# CC3200 register map
Vendor: Texas Instruments; File version: 1.0
SimpleLink™ 32-bit Arm Cortex-M4 Wi-Fi® wireless MCU with 2 TLS/SSL and 256kB RAM
CPU: CM4 r2p1, little endian, no MPU, no FPU, 3 interrupt priority bits
Registers are 32-bit, read-write, reset 0x0 unless marked. A register's access mark holds for its fields unless they carry their own. Offsets are from the block's base; lines under a group give offsets from that group; [hi:lo] are bit positions; {n}, {i} and the like mark numbered series; 'fields as' and 'values as' point back to an identical list; <NAME> marks a mode.

## Memory map
0x40000000 WDT size 0x1000 — Watchdog Timer
0x40004000 GPIOA0 size 0x1000 — General-Purpose Input/Output Port A0
0x40005000 GPIOA1 size 0x1000 — General-Purpose Input/Output Port A1
0x40006000 GPIOA2 size 0x1000 — General-Purpose Input/Output Port A2
0x40007000 GPIOA3 size 0x1000 — General-Purpose Input/Output Port A3
0x44025000 ARCM size 0x1000 — Application Reset-Clock Manager
0x4402E000 OCP_SHARED size 0x1000 — MCU Shared Configuration

## WDT — Watchdog Timer
Base 0x40000000
0x00 WDTLOAD reset 0xFFFFFFFF — Watchdog Load
  [31:0] WDTLOAD — Watchdog Load Value
0x04 WDTVALUE ro reset 0xFFFFFFFF — Watchdog Value
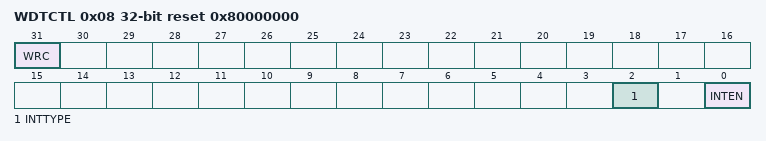
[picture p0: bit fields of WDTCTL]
0x08 WDTCTL reset 0x80000000 — Watchdog Control
  [31] WRC ro — Write Complete
  [2] INTTYPE — Watchdog Interrupt Type
  [0] INTEN — Watchdog Interrupt Enable
0x0C WDTICR wo reset not defined — Watchdog Interrupt Clear
  [31:0] WDTINTCLR
0x10 WDTRIS ro — Watchdog Raw Interrupt Status
  [0] WDTRIS
0x418 WDTTEST — Watchdog Test Mode
  [8] STALL — Watchdog Stall Enable
0xC00 WDTLOCK — Watchdog Lock

## GPIOA0 — General-Purpose Input/Output Port A0
Base 0x40004000
Same registers: GPIOA1 0x40005000, GPIOA2 0x40006000, GPIOA3 0x40007000
0x3FC GPIODATA
  [7:0] DATA
0x400 GPIODIR — GPIO Data Direction
  [7:0] DIR
0x404 GPIOIS — GPIO Interrupt Sense
  [7:0] IS
0x408 GPIOIBE — GPIO Interrupt Both Edges
  [7:0] IBE
0x40C GPIOIEV — GPIO Interrupt Event
  [7:0] IEV
0x410 GPIOIM — GPIO Interrupt Mask Enable
  [7:0] IM
0x414 GPIORIS — GPIO Interrupt Raw Status
  [7:0] RIS
0x418 GPIOMIS ro — GPIO Masked Interrupt Status
  [7:0] MIS
0x41C GPIOICR wo — GPIO Interrupt Clear
  [7:0] ICR

## ARCM — Application Reset-Clock Manager
Base 0x44025000
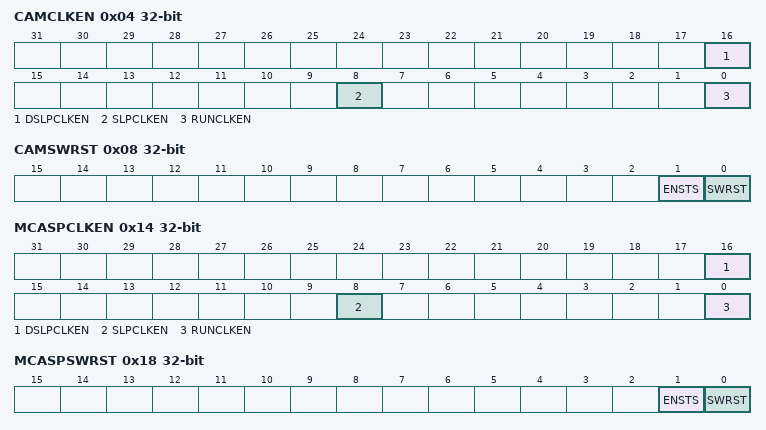
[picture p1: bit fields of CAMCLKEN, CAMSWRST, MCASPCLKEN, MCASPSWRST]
0x04 CAMCLKEN — Camera Clock Enable
  [16] DSLPCLKEN — Deepsleep Clock Enable
  [8] SLPCLKEN — Sleep Clock Enable
  [0] RUNCLKEN — Run Clock Enable
0x08 CAMSWRST — Camera Software Reset
  [1] ENSTS ro — Enable Status
  [0] SWRST — Software Reset
0x14 MCASPCLKEN — I2S Clock Enable
  fields as CAMCLKEN
0x18 MCASPSWRST — I2S Software Reset
  [1] ENSTS ro — Enable Status
  [0] SWRST — Software Reset
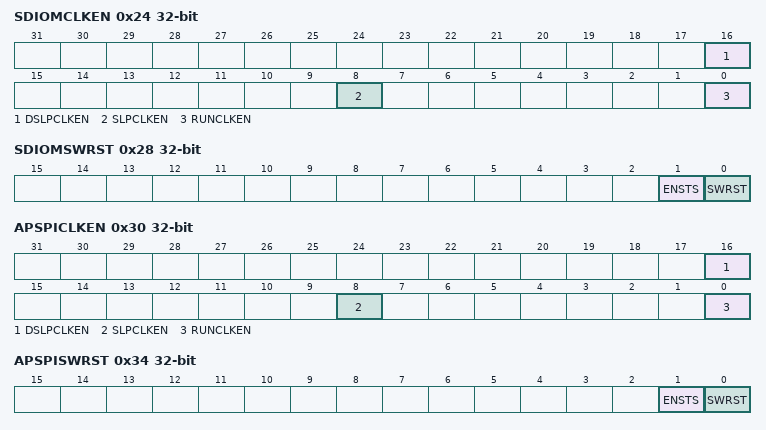
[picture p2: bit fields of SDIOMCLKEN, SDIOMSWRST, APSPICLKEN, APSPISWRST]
0x24 SDIOMCLKEN — SD Host Clock Enable
  fields as CAMCLKEN
0x28 SDIOMSWRST — SD Host Software Reset
  [1] ENSTS ro — Enable Status
  [0] SWRST — Software Reset
0x30 APSPICLKEN — SPI Clock Enable
  fields as CAMCLKEN
0x34 APSPISWRST — SPI Software Reset
  [1] ENSTS ro — Enable Status
  [0] SWRST — Software Reset
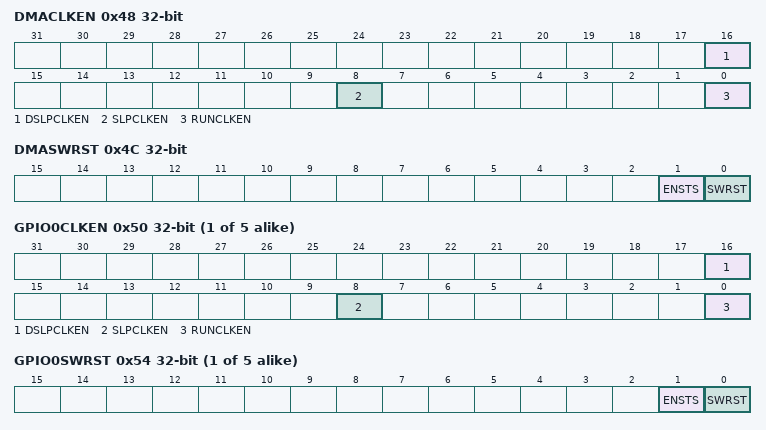
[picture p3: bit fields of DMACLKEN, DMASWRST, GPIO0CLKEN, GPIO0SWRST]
0x48 DMACLKEN — DMA Clock Enable
  fields as CAMCLKEN
0x4C DMASWRST — DMA Software Reset
  [1] ENSTS ro — Enable Status
  [0] SWRST — Software Reset
{0x50+8i} GPIO{i}CLKEN (i=0..4) — GPIO{i} Clock Enable
  fields as CAMCLKEN
{0x54+8i} GPIO{i}SWRST (i=0..4) — GPIO{i} Software Reset
  [1] ENSTS ro — Enable Status
  [0] SWRST — Software Reset
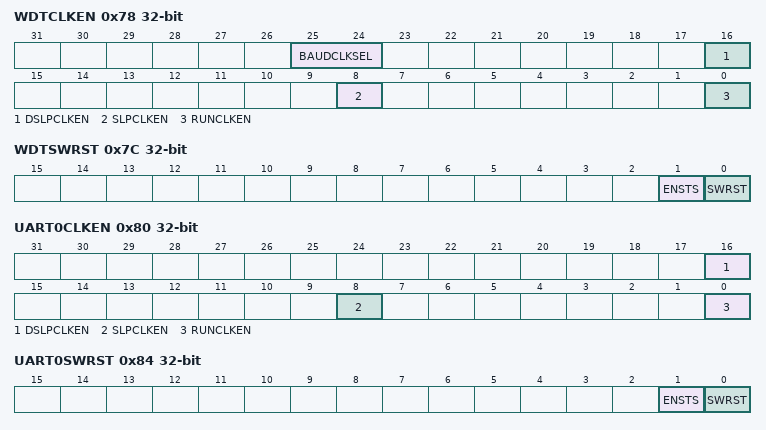
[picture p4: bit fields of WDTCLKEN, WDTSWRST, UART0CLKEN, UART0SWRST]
0x78 WDTCLKEN — Watchdog Clock Enable
  [25:24] BAUDCLKSEL — Baud Clock Select
  [16] DSLPCLKEN — Deepsleep Clock Enable
  [8] SLPCLKEN — Sleep Clock Enable
  [0] RUNCLKEN — Run Clock Enable
0x7C WDTSWRST — Watchdog Software Reset
  [1] ENSTS ro — Enable Status
  [0] SWRST — Software Reset
0x80 UART0CLKEN — UART0 Clock Enable
  fields as CAMCLKEN
0x84 UART0SWRST — UART0 Software Reset
  [1] ENSTS ro — Enable Status
  [0] SWRST — Software Reset
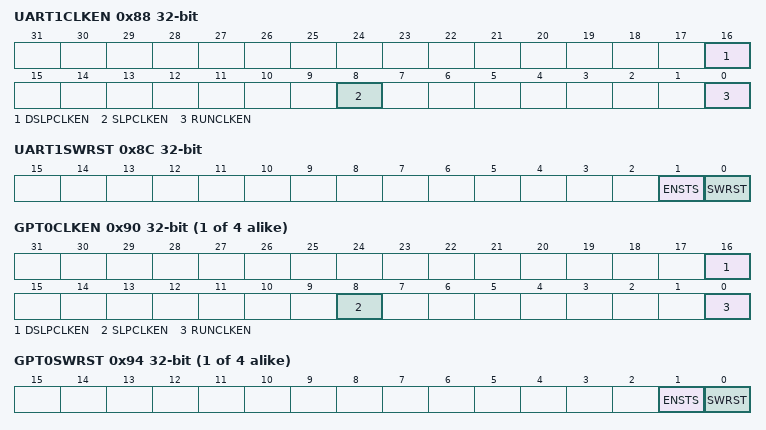
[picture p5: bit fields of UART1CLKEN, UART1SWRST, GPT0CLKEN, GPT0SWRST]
0x88 UART1CLKEN — UART1 Clock Enable
  fields as CAMCLKEN
0x8C UART1SWRST — UART1 Software Reset
  [1] ENSTS ro — Enable Status
  [0] SWRST — Software Reset
{0x90+8i} GPT{i}CLKEN (i=0..3) — GPT{i} Clock Enable
  fields as CAMCLKEN
{0x94+8i} GPT{i}SWRST (i=0..3) — GPT{i} Software Reset
  [1] ENSTS ro — Enable Status
  [0] SWRST — Software Reset
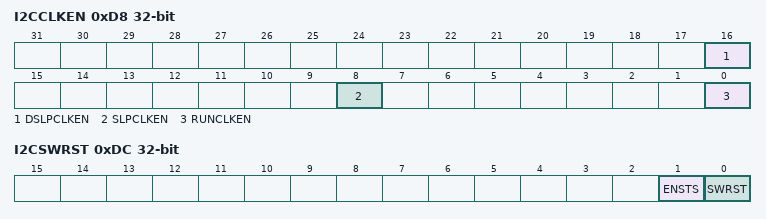
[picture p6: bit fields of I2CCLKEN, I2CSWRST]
0xD8 I2CCLKEN — I2C Clock Enable
  fields as CAMCLKEN
0xDC I2CSWRST — I2C Software Reset
  [1] ENSTS ro — Enable Status
  [0] SWRST — Software Reset
